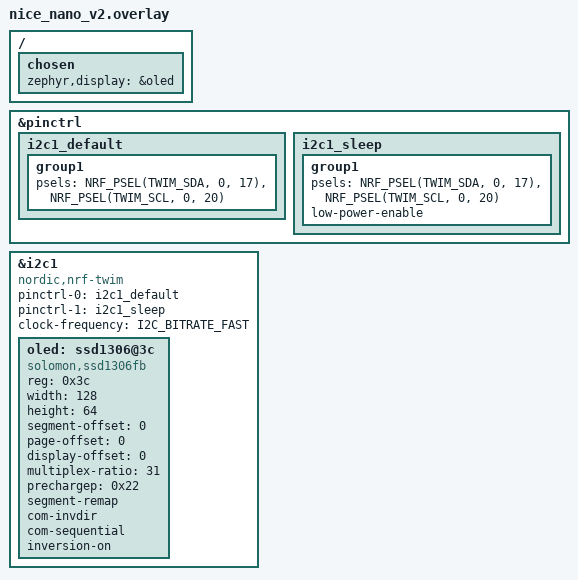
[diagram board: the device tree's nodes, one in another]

/**
 * Generated by Shield Wizard for ZMK
 * Applies to shield "whn_ff" with board "nice_nano_v2" only
 */

//
// ======== i2c1 ========
//

// pin control for i2c1
// - SDA on D2
// - SCL on D3
&pinctrl {
    /* configuration for i2c1 device, default state */
    i2c1_default: i2c1_default {
        group1 {
            psels = <NRF_PSEL(TWIM_SDA, 0, 17)>,
                    <NRF_PSEL(TWIM_SCL, 0, 20)>;
        };
    };
    /* configuration for i2c1 device, sleep state */
    i2c1_sleep: i2c1_sleep {
        group1 {
            psels = <NRF_PSEL(TWIM_SDA, 0, 17)>,
                    <NRF_PSEL(TWIM_SCL, 0, 20)>;
            low-power-enable;
        };
    };
};
&i2c1 {
  compatible = "nordic,nrf-twim";
  status = "okay";
  pinctrl-0 = <&i2c1_default>;
  pinctrl-1 = <&i2c1_sleep>;
  pinctrl-names = "default", "sleep";
  clock-frequency = <I2C_BITRATE_FAST>;
};

// devices on i2c1

&i2c1 {
    oled: ssd1306@3c {
        compatible = "solomon,ssd1306fb";
        reg = <0x3c>;
        width = <128>;
        height = <64>;

        segment-offset = <0>;
        page-offset = <0>;
        display-offset = <0>;
        multiplex-ratio = <31>;
        prechargep = <0x22>;
        segment-remap;
        com-invdir;
        com-sequential;
        inversion-on;
    };
};
/ {
    chosen {
        zephyr,display = &oled;
    };
};
